AUTOSAR XML (schema 4-3-0)
package /Impl_SWC_V2L_ARPkg
  swc implementation Impl_SWC_V2L_type: programming-language=C, sw-version=1.0.0, vendor-id=0, behavior=SWC_V2L_type_IB
    code-descriptors:
      code SRC: artifact-descriptors=autosar-engineering-object={short-label=EngObject, category=SWSRC}
    resource consumption ResourceConsumption
      memory section MEM_SWC_V2L_CAL: size=0, sw-addrmethod=CAL, symbol=CAL
      memory section MEM_SWC_V2L_CODE: size=0, sw-addrmethod=CODE, symbol=CODE
package /SWC_V2L_ARPkg
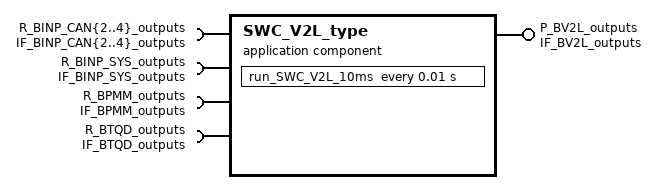
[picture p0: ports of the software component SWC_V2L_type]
  application sw component type SWC_V2L_type
    provide port P_BV2L_outputs: provided-interface=IF_BV2L_outputs
    6 x require port:
      R_BINP_CAN{2..4}_outputs: required-interface=IF_BINP_CAN{2..4}_outputs
      R_BINP_SYS_outputs: required-interface=IF_BINP_SYS_outputs
      R_BPMM_outputs: required-interface=IF_BPMM_outputs
      R_BTQD_outputs: required-interface=IF_BTQD_outputs
    behavior SWC_V2L_type_IB: data-type-mapping=AppModeTypeMap, handle-termination-and-restart=NO-SUPPORT
      timing event TE_V2L_10ms: start-on-event=run_SWC_V2L_10ms, period=0.01
      runnable run_SWC_V2L_10ms
        data-receive-point-by-arguments:
          6 x access:
            drparg_BINP_CAN{2..4}_outputs: accessed-variable=R_BINP_CAN{2..4}_outputs.BINP_CAN{2..4}_outputs
            drparg_BINP_SYS_outputs: accessed-variable=R_BINP_SYS_outputs.BINP_SYS_outputs
            drparg_BPMM_outputs: accessed-variable=R_BPMM_outputs.BPMM_outputs
            drparg_BTQD_outputs: accessed-variable=R_BTQD_outputs.BTQD_outputs
        data-send-points:
          access dsp_BV2L_outputs: accessed-variable=P_BV2L_outputs.BV2L_outputs
